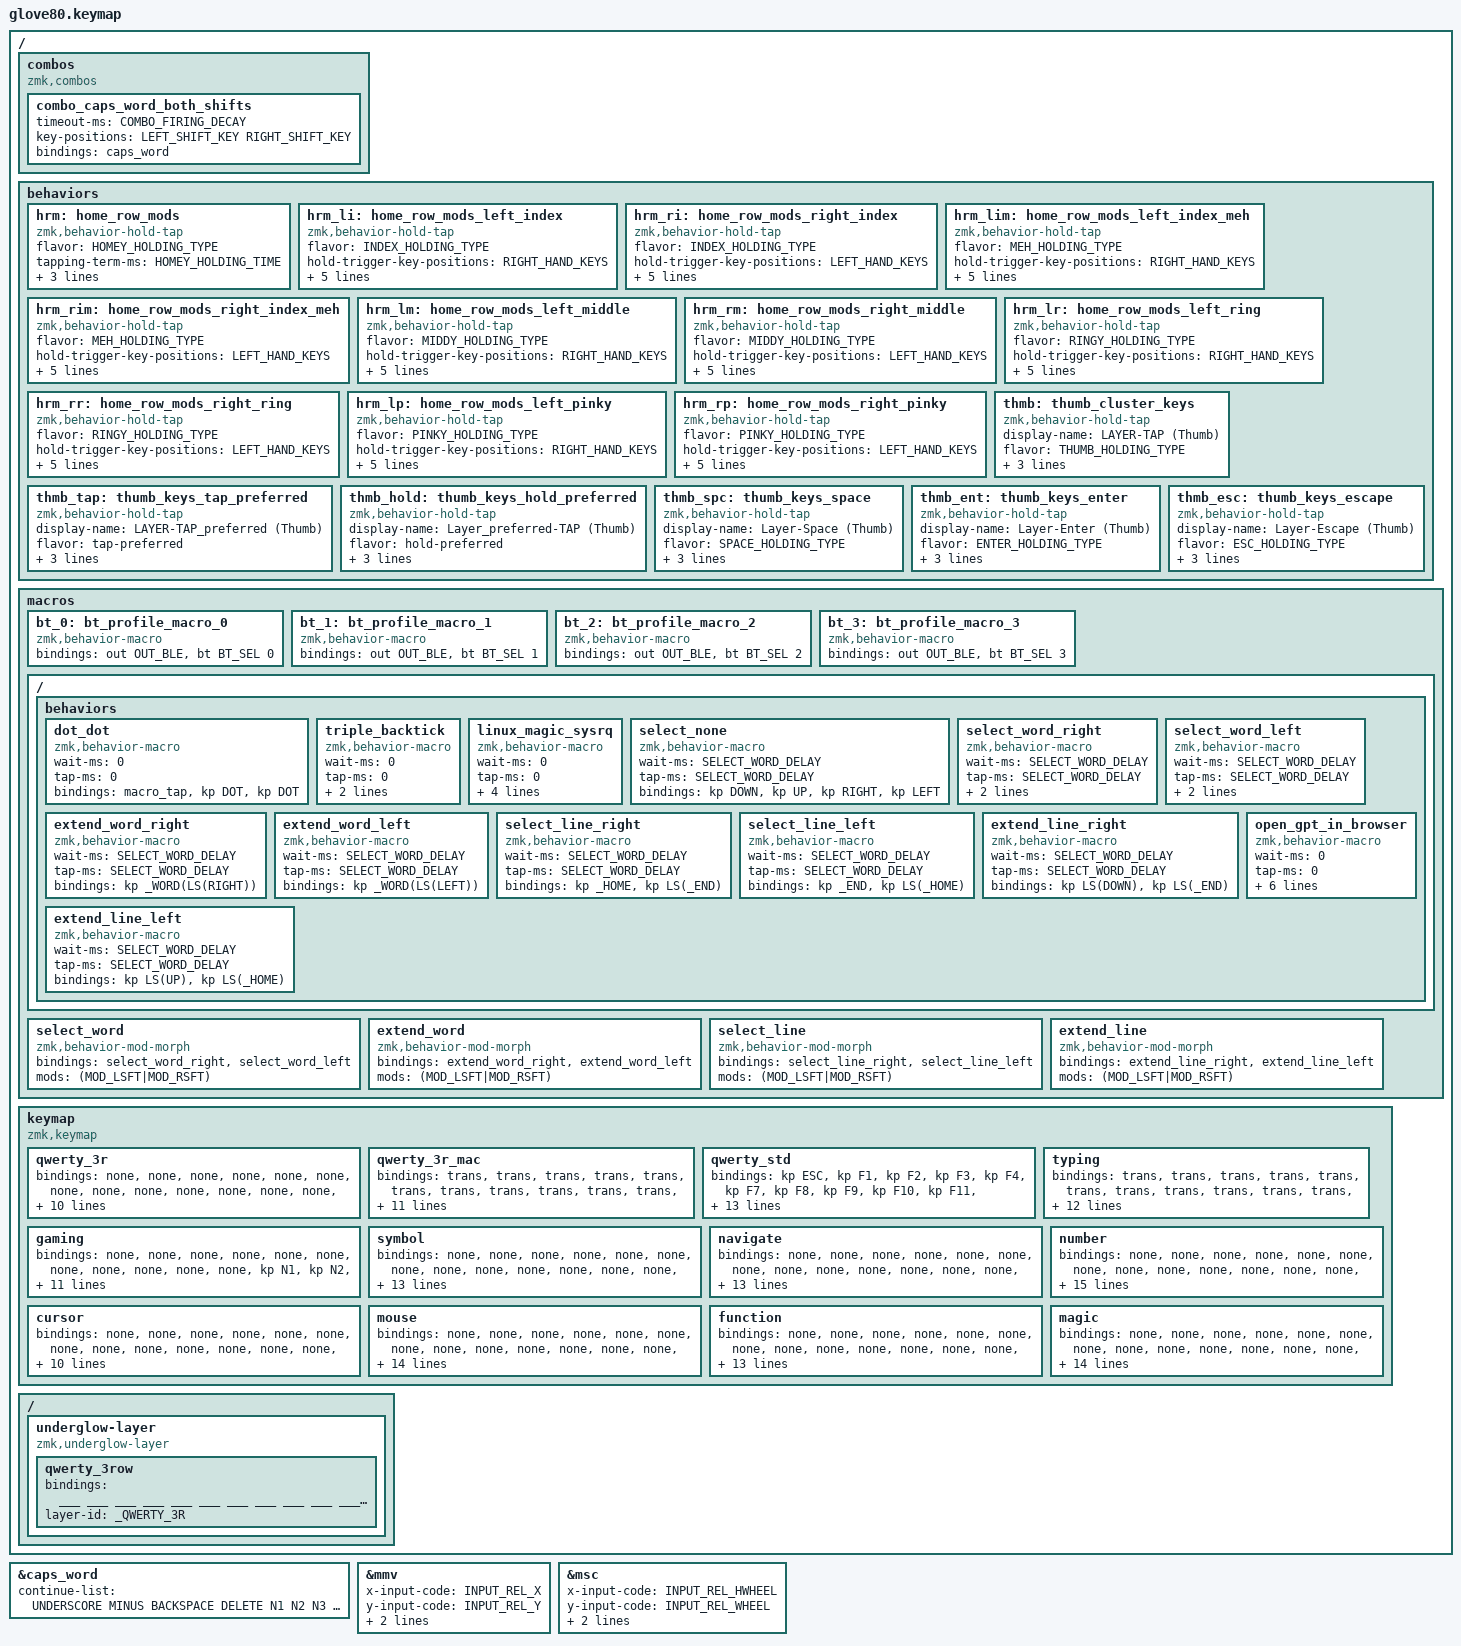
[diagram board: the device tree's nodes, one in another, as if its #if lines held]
/*
 * Copyright (c) 2020 The ZMK Contributors
 *
 * SPDX-License-Identifier: MIT
 */

// ########################################################################
// Import ZMK Device Tree Bindings
// ########################################################################
#include <behaviors.dtsi>
#include <dt-bindings/zmk/keys.h>
#include <dt-bindings/zmk/bt.h>
#include <dt-bindings/zmk/ext_power.h>
#include <dt-bindings/zmk/outputs.h>
#include <dt-bindings/zmk/rgb.h>

// ------------------------------------------------------------------------
// Mouse Emulation Bindings and configs
// ------------------------------------------------------------------------
#define ZMK_POINTING_DEFAULT_MOVE_VAL 1500  // default: 600
#define ZMK_POINTING_DEFAULT_SCRL_VAL 100    // default: 10

#include <dt-bindings/zmk/pointing.h>

// ########################################################################
// Define Key Positions
// ########################################################################

// ------------------------------------------------------------------------
// Define Key Position for each half
// ------------------------------------------------------------------------

// Glove80 key positions index for positional hold-tap
// - https://discord.com/channels/877392805654306816/937645688244826154/1066713913351221248
// - https://media.discordapp.net/attachments/937645688244826154/1066713913133121556/image.png
//
// |------------------------|------------------------|
// | LEFT_HAND_KEYS         |        RIGHT_HAND_KEYS |
// |                        |                        |
// |  0  1  2  3  4         |          5  6  7  8  9 |
// | 10 11 12 13 14 15      |      16 17 18 19 20 21 |
// | 22 23 24 25 26 27      |      28 29 30 31 32 33 |
// | 34 35 36 37 38 39      |      40 41 42 43 44 45 |
// | 46 47 48 49 50 51      |      58 59 60 61 62 63 |
// | 64 65 66 67 68         |         75 76 77 78 79 |
// |                69 52   |   57 74                |
// |                 70 53  |  56 73                 |
// |                  71 54 | 55 72                  |
// |------------------------|------------------------|
//

#define                                              \
     LEFT_HAND_KEYS                                  \
      0  1  2  3  4                                  \
     10 11 12 13 14 15                               \
     22 23 24 25 26 27                               \
     34 35 36 37 38 39                               \
     46 47 48 49 50 51                               \
     64 65 66 67 68                                  \
                    69 52                            \
                     70 53                           \
                      71 54
#define                                              \
                                     RIGHT_HAND_KEYS \
                                       5  6  7  8  9 \
                                   16 17 18 19 20 21 \
                                   28 29 30 31 32 33 \
                                   40 41 42 43 44 45 \
                                   58 59 60 61 62 63 \
                                      75 76 77 78 79 \
                                57 74                \
                               56 73                 \
                              55 72

// ------------------------------------------------------------------------
// Define Key Position for Home Row Mods (HRMs)
// ------------------------------------------------------------------------
#define LEFT_PINKY_KEY  35
#define LEFT_RINGY_KEY  36
#define LEFT_MIDDY_KEY  37
#define LEFT_INDEX_KEY  38
#define LEFT_MEH_KEY    39

#define RIGHT_MEH_KEY   40
#define RIGHT_INDEX_KEY 41
#define RIGHT_MIDDY_KEY 42
#define RIGHT_RINGY_KEY 43
#define RIGHT_PINKY_KEY 44

// ------------------------------------------------------------------------
// Define Shift Key Positions (used for caps word activation)
// ------------------------------------------------------------------------
#define LEFT_SHIFT_KEY  46
#define RIGHT_SHIFT_KEY 63

// ########################################################################
// Tap-Hold Configs
// ########################################################################

// ------------------------------------------------------------------------
// Set tapping TERMs
// ------------------------------------------------------------------------

// ........................................................................
// Guides
// ........................................................................

// Sunsaku's suggested TAPPING_TERM, based on difficulty:
// LEVEL 0 => sunaku (150ms)
// LEVEL 1 => novice (500ms)
// LEVEL 2 => slower (400ms)
// LEVEL 3 => normal (300ms)
// LEVEL 4 => faster (200ms)
// LEVEL 5 => expert (100ms)

// Tapping FLavors (flavor)
// hold_preferred:         (~QMK's HOLD_ON_OTHER_KEY_PRESS)(Good for Thumb keys)
// balanced:               (~QMK's PERMISSIVE_HOLD)
// tap-preferred:          (~QMK's default)(Good for Legato typing)
// tap-unless-interrupted:

// Quick Tap (quick_tap_ms): it's very useful for HRM keys that double as vim nav keys.

// require-prior-idle-ms: timeout for typing streak enforcement (~QMK's FLOW_TAP_TERM).

// ........................................................................
// migrated from QMK
// ........................................................................
#define TAPPING_TERM   150                   // The duration, after which, a key is considered held. Default: 200 (ms)
#define QUICK_TAP_TERM (TAPPING_TERM - 50)   // Time for "press then hold", for auto-repeat. Default: = TAPPING_TERM
#define FLOW_TAP_TERM  (TAPPING_TERM - 25)   // Disables holds when typing quickly. Default: 125 (ms)

// ........................................................................
// ZMK
// ........................................................................
// FIXME: just use TAPPING_TERM (so Vars used in QMK and ZMK are mutually consistent)
#define TAPPING_RESOLUTION TAPPING_TERM

// Home Row Mods (HRM)
#define HOMEY_HOLDING_TYPE "tap-preferred"             // Options: hold-preferred, balanced, tap-preferred
#define HOMEY_HOLDING_TIME (TAPPING_TERM + 90)         // HRM keys tapping TERM
#define HOMEY_FLOW_DECAY (FLOW_TAP_TERM)             // Defines how long to wait until you can use HRM keys again.
#define HOMEY_REPEAT_DECAY (QUICK_TAP_TERM)  // Time after a tap, during which holding the same key results in auto-repeat.
// CHORD (i.e., opposite-hand)
// FIXME:What is it for???
#define CHORD_HOLDING_TYPE HOMEY_HOLDING_TYPE          // Defines the flavor of ZMK hold-tap flavor for CHORD keys
#define CHORD_HOLDING_TIME TAPPING_RESOLUTION
#define CHORD_FLOW_DECAY HOMEY_FLOW_DECAY
#define CHORD_REPEAT_DECAY HOMEY_REPEAT_DECAY
// INDEX Finger
#define INDEX_HOLDING_TYPE HOMEY_HOLDING_TYPE
#define INDEX_HOLDING_TIME (TAPPING_RESOLUTION + 30)
#define INDEX_FLOW_DECAY HOMEY_FLOW_DECAY
#define INDEX_REPEAT_DECAY HOMEY_REPEAT_DECAY
// MEH Finger (Using Index Finger)
#define MEH_HOLDING_TYPE INDEX_HOLDING_TYPE
#define MEH_HOLDING_TIME (TAPPING_RESOLUTION + 45)
#define MEH_FLOW_DECAY HOMEY_FLOW_DECAY
#define MEH_REPEAT_DECAY HOMEY_REPEAT_DECAY
// MIDDLE Finger
#define MIDDY_HOLDING_TYPE HOMEY_HOLDING_TYPE
#define MIDDY_HOLDING_TIME (TAPPING_RESOLUTION + 60)
#define MIDDY_FLOW_DECAY HOMEY_FLOW_DECAY
#define MIDDY_REPEAT_DECAY HOMEY_REPEAT_DECAY
// RING Finger
#define RINGY_HOLDING_TYPE HOMEY_HOLDING_TYPE
#define RINGY_HOLDING_TIME (TAPPING_RESOLUTION + 90)
#define RINGY_FLOW_DECAY HOMEY_FLOW_DECAY
#define RINGY_REPEAT_DECAY HOMEY_REPEAT_DECAY
// PINKY Finger
#define PINKY_HOLDING_TYPE HOMEY_HOLDING_TYPE
#define PINKY_HOLDING_TIME (TAPPING_RESOLUTION + 120)
#define PINKY_FLOW_DECAY HOMEY_FLOW_DECAY
#define PINKY_REPEAT_DECAY HOMEY_REPEAT_DECAY
// THUMB KEYs
#define THUMB_HOLDING_TYPE "balanced"           // Options: hold-preferred, balanced (sunsaku's pref), tap-preferred
#define THUMB_HOLDING_TIME (TAPPING_TERM + 50)  // THUMB keys tapping TERM
#define THUMB_FLOW_DECAY TAPPING_TERM           // Defines how long to wait until you can use THUMB keys again.
#define THUMB_REPEAT_DECAY (QUICK_TAP_TERM)     // Time after a tap, during which holding the same key results in auto-repeat.
// SPACE thumb key
#define SPACE_HOLDING_TYPE THUMB_HOLDING_TYPE
#define SPACE_HOLDING_TIME (THUMB_HOLDING_TIME - 10)
#define SPACE_FLOW_DECAY THUMB_FLOW_DECAY
#define SPACE_REPEAT_DECAY THUMB_REPEAT_DECAY
// ENTER thumb key
#define ENTER_HOLDING_TYPE THUMB_HOLDING_TYPE
#define ENTER_HOLDING_TIME (THUMB_HOLDING_TIME - 25)
#define ENTER_FLOW_DECAY THUMB_FLOW_DECAY
#define ENTER_REPEAT_DECAY THUMB_REPEAT_DECAY
// ESC thumb key
#define ESC_HOLDING_TYPE THUMB_HOLDING_TYPE
#define ESC_HOLDING_TIME THUMB_HOLDING_TIME
#define ESC_FLOW_DECAY THUMB_FLOW_DECAY
#define ESC_REPEAT_DECAY THUMB_REPEAT_DECAY

// ........................................................................
// Miryoku
// ........................................................................
// TODO: too complicated, maybe it's better to just remove it
#define ENFORCE_BILATERAL  // Cancels out single-handed HRMs activation and replacing them with taps.

// ###############################################################
// Define Aliases
// ###############################################################

// ---------------------------------------------------------------
// Define Aliases: Layers
// ---------------------------------------------------------------
// NOTE: These are just aliases for layer numbers. The actual layer numbers are determined by the order of the layers in the keymap.
// If you change the order of the layers, you must also change the layer numbers below.

/* #define DEFAULT           0   // Glove80 default layer */
/* #define LOWER             1   // Glove80 lower layer */
/* #define MAGIC             2   // Glove80 magic layer */
#define _QWERTY_3R         0   // TekBoArt Base QWERTY layer (3-row)
#define _QWERTY_3R_MAC     1   // TekBoArt Base QWERTY layer (3-row)
#define _QWERTY_STD        2   // TekBoArt Base Standard layer
#define _TYPING            3   // TekBoArt Typing layer
#define _GAMING            4   // TekBoArt Gaming layer
#define _SYMBOL            5   // TekBoArt Symbol layer
#define _NAVIGATE          6   // TekBoArt Symbol layer
#define _NUMBER            7   // TekBoArt Number layer
#define _CURSOR            8   // TekBoArt Cursor layer
#define _MOUSE             9   // TekBoArt Cursor layer
#define _FUNCTION          10   // TekBoArt Function layer
#define _MAGIC             11  // Tekboart magic layer

// ---------------------------------------------------------------
// Define Aliases: Layer Switch/Activation
// ---------------------------------------------------------------
// (Base) QWERTY Layer (3-row)
#define TG_BASE  &tog _QWERTY_3R
#define TO_BASE  &to  _QWERTY_3R

// (Base) QWERTY Layer (3-row) -- MacOS
#define TG_BSMC  &tog _QWERTY_3R_MAC
#define TO_BSMC  &to  _QWERTY_3R_MAC

// (Base) QWERTY Layer (6-row)
#define TG_STD   &tog _QWERTY_STD
#define TO_STD   &to  _QWERTY_STD

// Typing Layer
#define TG_TYP   &tog _TYPING
#define TO_TYP   &to  _TYPING

// Gaming Layer
#define TG_GAME  &tog _GAMING
#define TO_GAME  &to  _GAMING

// --- Thumb Layer ---
// Symbol Layer
#define LT_SYM      &thmb_ent  _SYMBOL RET
#define LT_SYM_NAV  &thmb      _SYMBOL SM_BSLS  // SYM layer accessed through the NAV layer
#define MO_SYM      &mo        _SYMBOL
#define TG_SYM      &tog       _SYMBOL
#define TO_SYM      &to        _SYMBOL

// Navigation Layer
#define LT_NAV      &thmb_spc  _NAVIGATE SPC
#define LT_NAV_SYM  &thmb      _NAVIGATE SM_ADS // NAV layer accessed through the SYM layer
#define MO_NAV      &mo        _NAVIGATE
#define TG_NAV      &tog       _NAVIGATE
#define TO_NAV      &to        _NAVIGATE

// Number Layer
#define LT_NUM   &thmb_tap  _NUMBER TAB
#define MO_NUM   &mo  _NUMBER
#define TG_NUM   &tog _NUMBER
#define TO_NUM   &to  _NUMBER

// Cursor Layer
#define LT_CSR   &thmb_hold  _CURSOR N1
#define MO_CSR   &mo  _CURSOR
#define TG_CSR   &tog _CURSOR
#define TO_CSR   &to  _CURSOR

// Mouse Layer
#define LT_MSE   &thmb_hold  _MOUSE N1
#define MO_MSE   &mo  _MOUSE
#define TG_MSE   &tog _MOUSE
#define TO_MSE   &to  _MOUSE

// Function Layer
#define LT_FN    &thmb_esc  _FUNCTION ESC
#define MO_FN    &mo  _FUNCTION
#define TG_FN    &tog _FUNCTION
#define TO_FN    &to  _FUNCTION

// Magic Layer
#define MO_MGC   &mo  _MAGIC
#define TG_MGC   &tog _MAGIC
#define TO_MGC   &to  _MAGIC

// ------- Define Aliases: Mod-Tap Keys  -------
#define MT_LSFT &mt LSHIFT LBKT
#define MT_RSFT &mt RSHIFT RBKT
#define MT_RALT &mt RALT TAB

// ------- Define Aliases: Sticky Keys  -------
// Sticky keys remain active until the next key is pressed.
// They are useful for one-handed typing, e.g., first letter capital.
// Sticky Mods (OSM)
#define ST_LSFT &sk LSHIFT
#define ST_RSFT &sk RSHIFT


// ------- Define Aliases: Modifier Combinations  -------
#define MEH_L LA(LC(LSHFT))
#define MEH_R RA(RC(RSHFT))

// ------- Define Aliases: Home Row Mods (HRMs) -------
// for Win/Linux
#define HRW_LP   &hrm_lp  LGUI   A
#define HRW_LR   &hrm_lr  LALT   S
#define HRW_LM   &hrm_lm  LCTRL  D
#define HRW_LI   &hrm_li  LSHFT  F
#define HRW_LME  &hrm_lim MEH_L  G
#define HRW_RME  &hrm_rim MEH_R  H
#define HRW_RI   &hrm_ri  RSHFT  J
#define HRW_RM   &hrm_rm  RCTRL  K
#define HRW_RR   &hrm_rr  RALT   L
#define HRW_RP   &hrm_rp  RGUI   SEMI
// for MAC
#define HRM_LP   &hrm_lp  LCTRL  A
#define HRM_LR   &hrm_lr  LALT   S
#define HRM_LM   &hrm_lm  LGUI   D
#define HRM_LI   &hrm_li  LSHFT  F
#define HRM_LME  &hrm_lim MEH_L  G
#define HRM_RME  &hrm_rim MEH_R  H
#define HRM_RI   &hrm_ri  RSHFT  J
#define HRM_RM   &hrm_rm  RGUI   K
#define HRM_RR   &hrm_rr  RALT   L
#define HRM_RP   &hrm_rp  RCTRL  SEMI

// ------- Define Aliases: Symbols -------
#define SM_EXCL  EXCL // !
#define SM_ADS   AT // @
#define SM_HASH  HASH // #
#define SM_DLR   DLLR // $
#define SM_PERC  PRCNT // %
#define SM_CRET  CARET // ^
#define SM_AMPS  AMPS // &
#define SM_ASTR  ASTERISK // *
#define SM_LPRN  LPAR // (
#define SM_RPRN  RPAR // )
#define SM_LBRC  LBKT // [
#define SM_RBRC  RBKT // ]
#define SM_LCBR  LBRC // {
#define SM_RCBR  RBRC // }
#define SM_TICK  GRAVE // `
#define SM_TILD  TILDE // ~
#define SM_COMM  COMMA // ,
#define SM_LT    LT // <
#define SM_DOT   DOT // .
#define SM_GT    GT // >
#define SM_SLSH  FSLH // /
#define SM_QUES  QMARK // ?
#define SM_BSLS  BSLH // \ Backslash
#define SM_PIPE  PIPE // |
#define SM_COLN  COLON // :
#define SM_SCLN  SEMI // ;
#define SM_DQT   DQT // "
#define SM_QUOT  SQT // '
#define SM_EQL   EQUAL // =
#define SM_PLUS  PLUS // +
#define SM_MINS  MINUS // -
#define SM_UNDS  UNDER // _

// ------- Define Aliases: Media keys  -------
#define MD_MUTE  C_MUTE
#define MD_VOLU  C_VOL_UP
#define MD_VOLD  C_VOL_DN
#define MD_MPLY  C_PLAY_PAUSE
#define MD_MPRV  C_PREV
#define MD_MNXT  C_NEXT

// ------- Define Aliases: Misc keys  -------

// ---------------------------------------------------------------
// Define Aliases: OS specific actions
// ---------------------------------------------------------------
// Based on Sunsaku's: https://github.com/sunaku/glove80-keymaps
//
// OPERATING_SYSTEM defines which operating system you intend to use
// with this keymap, because shortcuts vary across operating systems.
//
// - https://zmk.dev/docs/codes
// - https://en.wikipedia.org/wiki/Table_of_keyboard_shortcuts
//
// This setting also affects the UNICODE() function defined below, as
// each OS has different shortcuts for typing Unicode hex characters.
//
// NOTE: You may need to enable Unicode hexadecimal input in your OS:
// - (macOS) https://uknowit.uwgb.edu/page.php?id=22623
//     and   https://github.com/ldanet/unicode-hex-input-fix
// - (Linux) https://help.ubuntu.com/stable/ubuntu-help/tips-specialchars.html.en#ctrlshiftu
// - (Windows) https://github.com/samhocevar/wincompose
//
// Specifically, Windows users should be running the WinCompose tool,
// which lets you type Unicode characters via hexadecimal codepoints.
//

// ...............................................................
// Define your preferred operating system
// ...............................................................
// TODO: can we detect the OS automatically? (like QMK does)
#ifndef OPERATING_SYSTEM
  #define OPERATING_SYSTEM 'L' // linux
//#define OPERATING_SYSTEM 'M' // macos
//#define OPERATING_SYSTEM 'W' // windows
#endif

// ...............................................................
// Define Windows, MacOS, and Linux specific key aliases
// ...............................................................
#if OPERATING_SYSTEM == 'W'
  #define _LOCK   LG(L)
#elif OPERATING_SYSTEM == 'M'
  #define _LOCK   _C(LC(Q))
#elif OPERATING_SYSTEM == 'L'
  #define _LOCK   K_LOCK
#endif

// ...............................................................
// Define Aliases that are different for MacOS, but similr for Linux and Windows
// ...............................................................
#if OPERATING_SYSTEM == 'M'
  #define _C      LG
  #define _POWER  K_POWER
  #define _GLOBE  GLOBE

  // The Text modifier--used for Getreuer's Select Word
  #define _WORD   LA

  // Define Aliases: Apps
  #define AP_FFOX ???
  #define AP_CHRM ???
  #define AP_TERM ???
  #define AP_FEXP &kp LS(LA(M))
  #define AP_SSHT LG(LS(N4))
  #define AP_EMOJ LA(LC(SPACE))
  #define AP_CALC  ???

  // Define Aliases: Editing
  #define _HOME   LG(LEFT)
  #define _END    LG(RIGHT)

#else
  #define _C      LC
  #define _POWER  C_POWER
  #define _GLOBE  LGUI

  // The Text modifier--used for Getreuer's Select Word
  #define _WORD   LC

  // Define Aliases: Apps
  #define AP_FFOX  LC(LA(LS(N1)))
  #define AP_CHRM  LC(LA(LS(N2)))
  #define AP_TERM  LC(LA(T))
  #define AP_FEXP  LG(E)
  #define AP_SSHT  LG(LS(S))
  #define AP_EMOJ  LG(DOT)
  #define AP_CALC  K_CALC

  // Define Aliases: Editing
  #define _HOME   HOME
  #define _END    END

#endif

// ...............................................................
// Define Aliases that are shared between MacOS, Linux, and Windows
// ...............................................................
#define _SLEEP      C_SLEEP

// ...............................................................
// Define Aliases that use os-agnostic custom aliases (defined above)
//
// e.g., _C is used for Ctrl on Linux/Windows and Cmd on MacOS
// ...............................................................

// Define Aliases: Editing
#define _UNDO       _C(Z)
#define _REDO       _C(LS(Z))
#define _CUT        _C(X)
#define _COPY       _C(C)
#define _PASTE      _C(V)
#define _FIND       _C(F)
#define _FIND_NEXT  _C(G)
#define _FIND_PREV  _C(LS(G))

// ########################################################################
// ZMK global overrides
// ########################################################################

// ------------------------------------------------------------------------
// CapsWord - ported from Pascal Getreuer's extension for QMK
// ------------------------------------------------------------------------

// - https://zmk.dev/docs/behaviors/caps-word
// - https://getreuer.info/posts/keyboards/caps-word/index.html
&caps_word {
  continue-list = <
    UNDERSCORE MINUS
    BACKSPACE DELETE
    N1 N2 N3 N4 N5 N6 N7 N8 N9 N0
    KP_N1 KP_N2 KP_N3 KP_N4 KP_N5 KP_N6 KP_N7 KP_N8 KP_N9 KP_N0
  >;
};


// ------------------------------------------------------------------------
// Mouse emulation
// ------------------------------------------------------------------------

// ------------------------------------------------------------------------
// Mouse Movement
// ------------------------------------------------------------------------
&mmv {
    x-input-code = <INPUT_REL_X>;
    y-input-code = <INPUT_REL_Y>;
    time-to-max-speed-ms = <300>;
    acceleration-exponent = <1>;
};

// ------------------------------------------------------------------------
// Mouse Scroll
// ------------------------------------------------------------------------
&msc {
    x-input-code = <INPUT_REL_HWHEEL>;
    y-input-code = <INPUT_REL_WHEEL>;
    time-to-max-speed-ms = <300>;
    acceleration-exponent = <0>;
};

/ {
    // ########################################################################
    // Define Custom Conditional Layers
    // ########################################################################
    // conditional_layers {
    //
    // TODO: Add Mac-specific keymaps and choose the appropiate one based on the base layer
    // e.g., if the base layer is _QWERTY_3R_MAC, then use _FUNCTION_MAC, else use _FUNCTION--the same goes for all the layers that have MAC-Specific keymaps.
    // NOTE: BUUUUUT, this way I need different versions of aliases, e.g., _HOME and _HOME_MAC.
    // };

    // ########################################################################
    // Define Custom Combinations (Combos)
    // ########################################################################
    combos {
        // -------------------------------------------------------
        // Adapted from Sunsaku's Glove80 keymap
        //
        // -  https://github.com/sunaku/glove80-keymaps/blob/main/keymap.dtsi
        // -------------------------------------------------------
        compatible = "zmk,combos";

        //
        // COMBO_FIRING_DECAY defines how much time you have left (milliseconds)
        // after pressing the first key in a ZMK combo to finish the whole chord.
        //
        #ifndef COMBO_FIRING_DECAY
        #define COMBO_FIRING_DECAY 80
        #endif

        //
        // SHIFT_FIRING_DECAY defines how much time you have left (milliseconds)
        // after pressing the first key in the one-shot sticky shift ZMK combo
        // (on index finger home + thumb cluster T1) to finish the whole chord.
        //
        #ifndef SHIFT_FIRING_DECAY
        #define SHIFT_FIRING_DECAY 50
        #endif

        // .......................................................
        // Caps Word Activation combo
        // .......................................................
        combo_caps_word_both_shifts {
            timeout-ms = <COMBO_FIRING_DECAY>;
            key-positions = <LEFT_SHIFT_KEY RIGHT_SHIFT_KEY>;
            bindings = <&caps_word>;
        };

        // TODO: Pressing magic key twice, will light up the assigned keys in magic key.

    };

    // ########################################################################
    // Define Custom behaviors
    // ########################################################################
    behaviors {
      // ------------------------------------------------------------------------
      //
      // Miryoku layers and home row mods (adapted from Sunsaku's Glove80 keymap)
      //
      // - https://sunaku.github.io/home-row-mods.html#porting-to-zmk
      // - https://github.com/urob/zmk-config#timeless-homerow-mods
      //
      // ------------------------------------------------------------------------

      // hrm
      hrm: home_row_mods {
          compatible = "zmk,behavior-hold-tap";
          flavor = HOMEY_HOLDING_TYPE;
          tapping-term-ms = <HOMEY_HOLDING_TIME>;
          quick-tap-ms = <HOMEY_REPEAT_DECAY>;
          require-prior-idle-ms = <HOMEY_FLOW_DECAY>;
          #binding-cells = <2>;
          bindings = <&kp>, <&kp>;
      };

      // hrm_index_finger (left)
      hrm_li: home_row_mods_left_index {
          compatible = "zmk,behavior-hold-tap";
          flavor = INDEX_HOLDING_TYPE;
          hold-trigger-key-positions = <RIGHT_HAND_KEYS>;
          hold-trigger-on-release; // wait for other home row mods
          tapping-term-ms = <INDEX_HOLDING_TIME>;
          quick-tap-ms = <INDEX_REPEAT_DECAY>;
          require-prior-idle-ms = <INDEX_FLOW_DECAY>;
          #binding-cells = <2>;
          bindings = <&kp>, <&kp>;
      };

      // hrm_index_finger (right)
      hrm_ri: home_row_mods_right_index {
          compatible = "zmk,behavior-hold-tap";
          flavor = INDEX_HOLDING_TYPE;
          hold-trigger-key-positions = <LEFT_HAND_KEYS>;
          hold-trigger-on-release; // wait for other home row mods
          tapping-term-ms = <INDEX_HOLDING_TIME>;
          quick-tap-ms = <INDEX_REPEAT_DECAY>;
          require-prior-idle-ms = <INDEX_FLOW_DECAY>;
          #binding-cells = <2>;
          bindings = <&kp>, <&kp>;
      };

      // hrm_index_finger_meh (left)
      hrm_lim: home_row_mods_left_index_meh {
          compatible = "zmk,behavior-hold-tap";
          flavor = MEH_HOLDING_TYPE;
          hold-trigger-key-positions = <RIGHT_HAND_KEYS>;
          hold-trigger-on-release; // wait for other home row mods
          tapping-term-ms = <MEH_HOLDING_TIME>;
          quick-tap-ms = <MEH_REPEAT_DECAY>;
          require-prior-idle-ms = <MEH_FLOW_DECAY>;
          #binding-cells = <2>;
          bindings = <&kp>, <&kp>;
      };

      // hrm_index_finger_meh (right)
      hrm_rim: home_row_mods_right_index_meh {
          compatible = "zmk,behavior-hold-tap";
          flavor = MEH_HOLDING_TYPE;
          hold-trigger-key-positions = <LEFT_HAND_KEYS>;
          hold-trigger-on-release; // wait for other home row mods
          tapping-term-ms = <MEH_HOLDING_TIME>;
          quick-tap-ms = <MEH_REPEAT_DECAY>;
          require-prior-idle-ms = <MEH_FLOW_DECAY>;
          #binding-cells = <2>;
          bindings = <&kp>, <&kp>;
      };

      // hrm_middle_finger (left)
      hrm_lm: home_row_mods_left_middle {
          compatible = "zmk,behavior-hold-tap";
          flavor = MIDDY_HOLDING_TYPE;
          hold-trigger-key-positions = <RIGHT_HAND_KEYS>;
          hold-trigger-on-release; // wait for other home row mods
          tapping-term-ms = <MIDDY_HOLDING_TIME>;
          quick-tap-ms = <MIDDY_REPEAT_DECAY>;
          require-prior-idle-ms = <MIDDY_FLOW_DECAY>;
          #binding-cells = <2>;
          bindings = <&kp>, <&kp>;
      };

      // hrm_middle_finger (right)
      hrm_rm: home_row_mods_right_middle {
          compatible = "zmk,behavior-hold-tap";
          flavor = MIDDY_HOLDING_TYPE;
          hold-trigger-key-positions = <LEFT_HAND_KEYS>;
          hold-trigger-on-release; // wait for other home row mods
          tapping-term-ms = <MIDDY_HOLDING_TIME>;
          quick-tap-ms = <MIDDY_REPEAT_DECAY>;
          require-prior-idle-ms = <MIDDY_FLOW_DECAY>;
          #binding-cells = <2>;
          bindings = <&kp>, <&kp>;
      };

      // hrm_ring_finger (left)
      hrm_lr: home_row_mods_left_ring {
          compatible = "zmk,behavior-hold-tap";
          flavor = RINGY_HOLDING_TYPE;
          hold-trigger-key-positions = <RIGHT_HAND_KEYS>;
          hold-trigger-on-release; // wait for other home row mods
          tapping-term-ms = <RINGY_HOLDING_TIME>;
          quick-tap-ms = <RINGY_REPEAT_DECAY>;
          require-prior-idle-ms = <RINGY_FLOW_DECAY>;
          #binding-cells = <2>;
          bindings = <&kp>, <&kp>;
      };

      // hrm_ring_finger (right)
      hrm_rr: home_row_mods_right_ring {
          compatible = "zmk,behavior-hold-tap";
          flavor = RINGY_HOLDING_TYPE;
          hold-trigger-key-positions = <LEFT_HAND_KEYS>;
          hold-trigger-on-release; // wait for other home row mods
          tapping-term-ms = <RINGY_HOLDING_TIME>;
          quick-tap-ms = <RINGY_REPEAT_DECAY>;
          require-prior-idle-ms = <RINGY_FLOW_DECAY>;
          #binding-cells = <2>;
          bindings = <&kp>, <&kp>;
      };

      // hrm_pinky_finger (left)
      hrm_lp: home_row_mods_left_pinky {
          compatible = "zmk,behavior-hold-tap";
          flavor = PINKY_HOLDING_TYPE;
          hold-trigger-key-positions = <RIGHT_HAND_KEYS>;
          hold-trigger-on-release; // wait for other home row mods
          tapping-term-ms = <PINKY_HOLDING_TIME>;
          quick-tap-ms = <PINKY_REPEAT_DECAY>;
          require-prior-idle-ms = <PINKY_FLOW_DECAY>;
          #binding-cells = <2>;
          bindings = <&kp>, <&kp>;
      };

      // hrm_pinky_finger (right)
      hrm_rp: home_row_mods_right_pinky {
          compatible = "zmk,behavior-hold-tap";
          flavor = PINKY_HOLDING_TYPE;
          hold-trigger-key-positions = <LEFT_HAND_KEYS>;
          hold-trigger-on-release; // wait for other home row mods
          tapping-term-ms = <PINKY_HOLDING_TIME>;
          quick-tap-ms = <PINKY_REPEAT_DECAY>;
          require-prior-idle-ms = <PINKY_FLOW_DECAY>;
          #binding-cells = <2>;
          bindings = <&kp>, <&kp>;
      };

      // thumb
      thmb: thumb_cluster_keys {
          compatible = "zmk,behavior-hold-tap";
          display-name = "LAYER-TAP (Thumb)";
          flavor = THUMB_HOLDING_TYPE;
          tapping-term-ms = <THUMB_HOLDING_TIME>;
          quick-tap-ms = <THUMB_REPEAT_DECAY>;
          #binding-cells = <2>;
          bindings = <&mo>, <&kp>;
      };

      // THUMB cluster keys
      // NOTE: Don't use `require-prior-idle-ms` for thumb keys, as it make them part of the flow, hence unwanted taps.

      // thumb tap
      thmb_tap: thumb_keys_tap_preferred {
          compatible = "zmk,behavior-hold-tap";
          display-name = "LAYER-TAP_preferred (Thumb)";
          flavor = "tap-preferred";
          tapping-term-ms = <THUMB_HOLDING_TIME>;
          quick-tap-ms = <THUMB_REPEAT_DECAY>;
          #binding-cells = <2>;
          bindings = <&mo>, <&kp>;
      };

      // thumb hold
      thmb_hold: thumb_keys_hold_preferred {
          compatible = "zmk,behavior-hold-tap";
          display-name = "Layer_preferred-TAP (Thumb)";
          flavor = "hold-preferred";
          tapping-term-ms = <THUMB_HOLDING_TIME>;
          quick-tap-ms = <THUMB_REPEAT_DECAY>;
          #binding-cells = <2>;
          bindings = <&mo>, <&kp>;
      };

      // thumb (tap: space)
      thmb_spc: thumb_keys_space {
          compatible = "zmk,behavior-hold-tap";
          display-name = "Layer-Space (Thumb)";
          flavor = SPACE_HOLDING_TYPE;
          tapping-term-ms = <SPACE_HOLDING_TIME>;  // I found 14Oms to be a good tradeoff.
          quick-tap-ms = <SPACE_REPEAT_DECAY>;
          #binding-cells = <2>;
          bindings = <&mo>, <&kp>;
      };

      // thumb (tap: enter)
      thmb_ent: thumb_keys_enter {
          compatible = "zmk,behavior-hold-tap";
          display-name = "Layer-Enter (Thumb)";
          flavor = ENTER_HOLDING_TYPE;
          tapping-term-ms = <ENTER_HOLDING_TIME>;  // I found 125ms to a good tradeoff.
          quick-tap-ms = <ENTER_REPEAT_DECAY>;
          #binding-cells = <2>;
          bindings = <&mo>, <&kp>;
      };

      // thumb (tap: escape)
      thmb_esc: thumb_keys_escape {
          compatible = "zmk,behavior-hold-tap";
          display-name = "Layer-Escape (Thumb)";
          flavor = ESC_HOLDING_TYPE;
          tapping-term-ms = <ESC_HOLDING_TIME>;  // I found 130ms to a good tradeoff.
          quick-tap-ms = <ESC_REPEAT_DECAY>;
          #binding-cells = <2>;
          bindings = <&mo>, <&kp>;
      };

    };

    // ########################################################################
    // Macros
    // ########################################################################
    macros {

        // -------------------------------------------------------
        // Glove80 Bluetooth buttons
        // -------------------------------------------------------
        bt_0: bt_profile_macro_0 {
            compatible = "zmk,behavior-macro";
            #binding-cells = <0>;
            bindings
                = <&out OUT_BLE>,
                  <&bt BT_SEL 0>;
        };
        #define BT_PRF0 &bt_0

        bt_1: bt_profile_macro_1 {
            compatible = "zmk,behavior-macro";
            #binding-cells = <0>;
            bindings
                = <&out OUT_BLE>,
                  <&bt BT_SEL 1>;
        };
        #define BT_PRF1 &bt_1

        bt_2: bt_profile_macro_2 {
            compatible = "zmk,behavior-macro";
            #binding-cells = <0>;
            bindings
                = <&out OUT_BLE>,
                  <&bt BT_SEL 2>;
        };
        #define BT_PRF2 &bt_2

        bt_3: bt_profile_macro_3 {
            compatible = "zmk,behavior-macro";
            #binding-cells = <0>;
            bindings
                = <&out OUT_BLE>,
                  <&bt BT_SEL 3>;
        };
        #define BT_PRF3 &bt_3

        // -------------------------------------------------------
        // Copied from Sunsaku's Glove80 keymap
        //
        // -  https://github.com/sunaku/glove80-keymaps/blob/main/keymap.dtsi
        // -------------------------------------------------------

        // .......................................................
        // Output two dots
        // .......................................................
        ZMK_MACRO(dot_dot,
            wait-ms = <0>;
            tap-ms = <0>;
            bindings = <&macro_tap &kp DOT &kp DOT>;
        )

        // .......................................................
        // Output three backticks (```), used for code blocks in Markdown or other formats.
        // .......................................................

        ZMK_MACRO(triple_backtick,
            wait-ms = <0>;
            tap-ms = <0>;
            bindings = <&macro_tap &kp GRAVE &kp GRAVE &kp GRAVE>;
        )
        #define MC_TICK &triple_backtick

        // .......................................................
        // Linux Magic System Request Key - hold this down and type REISUB
        //
        // - https://www.kernel.org/doc/html/latest/admin-guide/sysrq.html
        // - https://github.com/manna-harbour/miryoku/discussions/259
        // - https://unix.stackexchange.com/a/143955 (use LALT, not RALT)
        // .......................................................
        ZMK_MACRO(linux_magic_sysrq,
            wait-ms = <0>;
            tap-ms = <0>;
            bindings
            = <&macro_press &mo 0 &kp LALT>
            , <&macro_tap &kp PRINTSCREEN>
            , <&macro_pause_for_release>
            , <&macro_release &mo 0 &kp LALT>
            ;
        )

        // -------------------------------------------------------
        //
        // Approximation of Pascal Getreuer's Select Word macro from QMK
        // - https://getreuer.info/posts/keyboards/select-word/index.html
        //
        // -------------------------------------------------------

        // SELECT_WORD_DELAY defines how long the macro waits (milliseconds)
        // after moving the cursor before it selects a word.  A larger delay
        // may allow the macro to move to the next word upon each invocation.
        #ifndef SELECT_WORD_DELAY
        #define SELECT_WORD_DELAY 1
        #endif

        #define select_all kp _C(A)
        #define SEL_ALL &select_all

        ZMK_MACRO(select_none,
            wait-ms = <SELECT_WORD_DELAY>;
            tap-ms = <SELECT_WORD_DELAY>;
            bindings = <&kp DOWN &kp UP &kp RIGHT &kp LEFT>;
        )

        // select a word (jumps to next word upon each successive invocation)
        select_word: select_word {
            compatible = "zmk,behavior-mod-morph";
            #binding-cells = <0>;
            bindings = <&select_word_right>, <&select_word_left>;
            mods = <(MOD_LSFT|MOD_RSFT)>;
        };
        ZMK_MACRO(select_word_right,
            wait-ms = <SELECT_WORD_DELAY>;
            tap-ms = <SELECT_WORD_DELAY>;
            bindings = <&kp _WORD(RIGHT) &kp _WORD(LEFT) &kp _WORD(LS(RIGHT))>;
        )
        ZMK_MACRO(select_word_left,
            wait-ms = <SELECT_WORD_DELAY>;
            tap-ms = <SELECT_WORD_DELAY>;
            bindings = <&kp _WORD(LEFT) &kp _WORD(RIGHT) &kp _WORD(LS(LEFT))>;
        )
        // FIXME: The SEL_WRD does not extend the selection by repeated presses, as it would in QMK.
        #define SEL_WRD &select_word

        // extend current selection by one word
        extend_word: extend_word {
            compatible = "zmk,behavior-mod-morph";
            #binding-cells = <0>;
            bindings = <&extend_word_right>, <&extend_word_left>;
            mods = <(MOD_LSFT|MOD_RSFT)>;
        };
        ZMK_MACRO(extend_word_right,
            wait-ms = <SELECT_WORD_DELAY>;
            tap-ms = <SELECT_WORD_DELAY>;
            bindings = <&kp _WORD(LS(RIGHT))>;
        )
        ZMK_MACRO(extend_word_left,
            wait-ms = <SELECT_WORD_DELAY>;
            tap-ms = <SELECT_WORD_DELAY>;
            bindings = <&kp _WORD(LS(LEFT))>;
        )

        // select current line
        select_line: select_line {
            compatible = "zmk,behavior-mod-morph";
            #binding-cells = <0>;
            bindings = <&select_line_right>, <&select_line_left>;
            mods = <(MOD_LSFT|MOD_RSFT)>;
        };
        ZMK_MACRO(select_line_right,
            wait-ms = <SELECT_WORD_DELAY>;
            tap-ms = <SELECT_WORD_DELAY>;
            bindings = <&kp _HOME &kp LS(_END)>;
        )
        ZMK_MACRO(select_line_left,
            wait-ms = <SELECT_WORD_DELAY>;
            tap-ms = <SELECT_WORD_DELAY>;
            bindings = <&kp _END &kp LS(_HOME)>;
        )
        #define SEL_LNE &select_line

        //
        // extend current selection by one line
        //
        extend_line: extend_line {
            compatible = "zmk,behavior-mod-morph";
            #binding-cells = <0>;
            bindings = <&extend_line_right>, <&extend_line_left>;
            mods = <(MOD_LSFT|MOD_RSFT)>;
        };
        ZMK_MACRO(extend_line_right,
            wait-ms = <SELECT_WORD_DELAY>;
            tap-ms = <SELECT_WORD_DELAY>;
            bindings = <&kp LS(DOWN) &kp LS(_END)>;
        )
        ZMK_MACRO(extend_line_left,
            wait-ms = <SELECT_WORD_DELAY>;
            tap-ms = <SELECT_WORD_DELAY>;
            bindings = <&kp LS(UP) &kp LS(_HOME)>;
        )


        // -------------------------------------------------------
        // ME macros
        // -------------------------------------------------------
        // .......................................................
        // Open ChatGPT in (default) Browser.
        // .......................................................
        ZMK_MACRO(open_gpt_in_browser,
            wait-ms = <0>;
            tap-ms = <0>;
            bindings
                // Launch or focus Firefox using your existing shortcut.
                = <&kp AP_FFOX>
                // Allow Firefox to start/focus.
                , <&macro_wait_time 1200>
                // Focus the address bar.
                , <&kp LC(L)>
                // Allow the address bar to receive focus.
                , <&macro_wait_time 50>
                // Type the first URL character after the 50 ms delay.
                , <&kp H>
                // Use the normal inter-key delay for the remaining URL.
                , <&macro_wait_time 30>
                // https
                , <&kp T &kp T &kp P &kp S>
                // ://
                , <&kp COLON &kp FSLH &kp FSLH>
                // chatgpt
                , <&kp C &kp H &kp A &kp T>
                , <&kp G &kp P &kp T>
                // .com/
                , <&kp DOT &kp C &kp O &kp M &kp FSLH>
                // Press Enter
                , <&kp ENTER>
                ;
        // };
        )
        #define MC_GPT &open_gpt_in_browser

    };

    // ########################################################################
    // Define Keymaps
    // ########################################################################
    keymap {
        compatible = "zmk,keymap";

        /* <layer_name> { */
        /*     bindings = < */
        /*     &none      &none    &none       &none       &none                                                                                                          &none      &none      &none      &none      &none */
        /*     &none      &none    &none       &none       &none       &none                                                                                   &none      &none      &none      &none      &none      &none */
        /*     &none      &none    &none       &none       &none       &none                                                                                   &none      &none      &none      &none      &none      &none */
        /*     &none      &none    &none       &none       &none       &none                                                                                   &none      &none      &none      &none      &none      &none */
        /*     &none      &none    &none       &none       &none       &none      &none      &none      &none      &none      &none      &none      &none      &none      &none      &none      &none      &none */
        /*     &none      &none    &none       &none       &none                  &none      &none      &none      &none      &none      &none */
        /*     >; */
        /* }; */

        /* default_layer { */
        /*     // --------------------------------------------------------------------------------------------------------------------------------- */
        /*     // |  F1   |  F2  |  F3  |  F4  |  F5  |                                                               |  F6   |  F7   |  F8  |  F9  |  F10 | */
        /*     // |  =    |   1  |   2  |   3  |   4  |  5   |                                                 |  6   |   7   |   8   |   9  |   0  |   -  | */
        /*     // |  TAB  |   Q  |   W  |   E  |   R  |  T   |                                                 |  Y   |   U   |   I   |   O  |   P  |   \  | */
        /*     // |  ESC  |   A  |   S  |   D  |   F  |  G   |                                                 |  H   |   J   |   K   |   L  |   ;  |   '  | */
        /*     // |   `   |   Z  |   X  |   C  |   V  |  B   | LSHFT | LCTRL | LOWER | | LGUI  | RCTRL | RSHFT |  N   |   M   |   ,   |   .  |   /  | PGUP | */
        /*     // | _MAGIC | HOME |  END | LEFT | RIGHT|      | BSPC  | DEL   | LALT  | | RALT  | RET   | SPACE |      |  UP   | DOWN  |   [  |   ]  | PGDN | */
        /*  */
        /*     bindings = < */
            /* &trans    &trans    &trans    &trans    &trans                                                                                    &trans    &trans    &trans    &trans    &trans */
            /* &trans    &trans    &trans    &trans    &trans    &trans                                                                &trans    &trans    &trans    &trans    &trans    &trans */
            /* &trans    &trans    &trans    &trans    &trans    &trans                                                                &trans    &trans    &trans    &trans    &trans    &trans */
            /* &trans    &trans    &trans    &trans    &trans    &trans                                                                &trans    &trans    &trans    &trans    &trans    &trans */
            /* &trans    &trans    &trans    &trans    &trans    &trans    &trans    &trans    &trans    &trans    &trans    &trans    &trans    &trans    &trans    &trans    &trans    &trans */
            /* &trans    &trans    &trans    &trans    &trans              &trans    &trans    &trans    &trans    &trans    &trans              &trans    &trans    &trans    &trans    &trans */
        /*     >; */
        /* }; */

        qwerty_3r {
            bindings = <
            &none     &none     &none     &none     &none                                                                                     &none     &none     &none     &none     &none
            &none     &none     &none     &none     &none     &none                                                                 &none     &none     &none     &none     &none     &none
            &kp LBKT  &kp Q     &kp W     &kp E     &kp R     &kp T                                                                 &kp Y     &kp U     &kp I     &kp O     &kp P     &kp RBKT
            &kp BSPC  HRW_LP    HRW_LR    HRW_LM    HRW_LI    HRW_LME                                                               HRW_RME   HRW_RI    HRW_RM    HRW_RR    HRW_RP    &kp SQT
            ST_LSFT   &kp Z     &kp X     &kp C     &kp V     &kp B     LT_NUM    LT_NAV    &none     &none     LT_SYM    LT_FN     &kp N     &kp M     &kp COMMA &kp DOT   &kp FSLH  ST_RSFT
            MO_MGC    &none     &none     &none     &none               MO_CSR    &none     &none     &none     &none     MO_MSE              &none     &none     &none     &none     MO_MGC
            >;
        };

        qwerty_3r_mac{
            bindings = <
            &trans    &trans    &trans    &trans    &trans                                                                                    &trans    &trans    &trans    &trans    &trans
            &trans    &trans    &trans    &trans    &trans    &trans                                                                &trans    &trans    &trans    &trans    &trans    &trans
            &trans    &trans    &trans    &trans    &trans    &trans                                                                &trans    &trans    &trans    &trans    &trans    &trans
            &trans    HRM_LP    HRM_LR    HRM_LM    HRM_LI    HRM_LME                                                               HRM_RME   HRM_RI    HRM_RM    HRM_RR    HRM_RP    &trans
            &trans    &trans    &trans    &trans    &trans    &trans    &trans    &trans    &trans    &trans    &trans    &trans    &trans    &trans    &trans    &trans    &trans    &trans
            &trans    &trans    &trans    &trans    &trans              &trans    &trans    &trans    &trans    &trans    &trans              &trans    &trans    &trans    &trans    &trans
            >;
        };

        qwerty_std {
            bindings = <
            &kp ESC    &kp F1    &kp F2      &kp F3      &kp F4                                                                                               &kp F7  &kp F8      &kp F9      &kp F10     &kp F11
            &kp GRAVE  &kp N1    &kp N2      &kp N3      &kp N4      &kp N5                                                                           &kp N6  &kp N7  &kp N8      &kp N9      &kp N0      &kp F12
            &kp TAB    &kp Q     &kp W       &kp E       &kp R       &kp T                                                                            &kp Y   &kp U   &kp I       &kp O       &kp P       &kp BSLH
            &kp CAPS   &kp A     &kp S       &kp D       &kp F       &kp G                                                                            &kp H   &kp J   &kp K       &kp L       &kp SEMI    &kp SQT
            &kp LSHIFT &kp Z     &kp X       &kp C       &kp V       &kp B   &kp DEL     &kp HOME   &kp PGUP  &kp RET   &kp UP    &kp BSPC            &kp N   &kp M   &kp COMMA   &kp DOT     &kp FSLH    &kp RSHFT
            MO_MGC     &kp LCTRL &kp LALT    &kp LGUI    &kp F5              &kp SPACE   &kp END    &kp PGDN  &kp LEFT  &kp DOWN  &lt _FUNCTION RIGHT         &kp F6  &kp LBKT    &kp RBKT    &kp MINUS   &kp EQUAL
            >;
        };

        typing {
            bindings = <
            &trans     &trans    &trans      &trans      &trans                                                                                             &trans  &trans      &trans      &trans      &trans
            &trans     &trans    &trans      &trans      &trans      &trans                                                                         &trans  &trans  &trans      &trans      &trans      &trans
            &trans     &trans    &trans      &trans      &trans      &trans                                                                         &trans  &trans  &trans      &trans      &trans      &trans
            &trans     &kp A     &kp S       &kp D       &kp F       &kp G                                                                          &kp H   &kp J   &kp K       &kp L       &kp SEMI    &trans
            &trans     &trans    &trans      &trans      &trans      &trans    &trans      &trans       &trans      &trans     &trans     &trans    &trans  &trans   &trans     &trans      &trans      &trans
            &trans     &trans    &trans      &trans      &trans                &trans      &trans       &trans      &trans     &trans     &trans            &trans   &trans     &trans      &trans      &trans
            >;
        };


        // TODO: Finalize gaming layer to match my QMK
        gaming {
            bindings = <
            &none     &none     &none     &none     &none                                                                                   &none    &none      &none       &none       &none
            &none     &kp N1    &kp N2    &kp N3    &kp N4    &kp N5                                                                &kp N6  &kp N7   &kp N8     &kp N9      &kp N0      &none
            &kp M     &kp TAB   &kp Q     &kp W     &kp E     &kp R                                                                 &none   &none    &kp UP     &none       &none       &none
            &kp I     &kp ESC   &kp A     &kp S     &kp D     &kp F                                                                 &none   &kp LEFT &kp DOWN   &kp RIGHT   &none       &none
            &kp G     &kp LSHFT &kp Z     &kp X     &kp C     &kp V     &kp LALT  LT_NAV    &none     &none     &trans    &trans    &none   &none    &none      &none       &none       &none
            &trans    &none     &none     &none     &none               &kp LGUI  &none     &none     &none     &none     &trans            &none    &none      &none       &none       &trans
            >;
        };

        symbol {
            bindings = <
            &none        &none        &none        &none        &none                                                                                                     &none     &none     &none     &none     &none
            &none        &none        &none        &none        &none         &none                                                                             &none     &none     &none     &none     &none     &none
            &kp SM_EXCL  &kp N1       &kp N2       &kp N3       &kp N4        &kp N5                                                                            &kp N6    &kp N7    &kp N8    &kp N9    &kp N0    &none
            &kp SM_HASH  &kp SM_CRET  &kp SM_EQL   &kp SM_UNDS  &kp SM_DLR    &kp SM_ASTR                                                                       &none     &kp RSHFT &kp RCTRL &kp RALT  &kp RGUI  MC_TICK
            &kp SM_AMPS  &kp SM_LT    &kp SM_PIPE  &kp SM_MINS  &kp SM_GT     &kp SM_PLUS   &kp SM_PERC   LT_NAV_SYM    &trans    &trans    &trans    &trans    &kp TAB   &kp SPC   &kp RET   &kp BSPC  &kp DEL   &none
            &trans       &none        &none        &none        &none                       &trans        &trans        &trans    &trans    &trans    &trans              &none     &none     &none     &none     &trans
            >;
        };

        // TODO: add DEL_NORM
        navigate {
            bindings = <
            &none     &none     &none     &none      &none                                                                                                   &none         &none         &none         &none         &none
            &none     &none     &none     &none      &none       &none                                                                         &none         &none         &none         &none         &none         &none
            &none     &kp N1    &kp N2    &kp N3     &kp N4      &kp N5                                                                        &kp N6        &kp N7        &kp N8        &kp N9        &kp N0        &none
            &kp DEL   &kp LGUI  &kp LALT  &kp LCTRL  &kp LSHFT   SEL_WRD                                                                       &kp _HOME     &kp LEFT      &kp DOWN      &kp UP        &kp RIGHT     &kp _END
            &none     &kp _UNDO &kp _CUT  &kp _COPY  &kp _PASTE  SEL_LNE   &trans    &trans    &trans    &trans    LT_SYM_NAV    &kp SM_TICK   &kp SM_LBRC   &kp SM_LCBR   &kp SM_LPRN   &kp SM_RPRN   &kp SM_RCBR   &kp SM_RBRC
            &trans    &none     &none     &none      &none                 &trans    &trans    &trans    &trans    &trans        &trans                      &none         &none         &none         &none         &trans
            >;
        };

        number {
            bindings = <
            &none        &none      &none      &none      &none                                                                                           &none      &none      &none      &none            &none
            &none        &none      &none      &none      &none       &none                                                                   &none       &none      &none      &none      &none            &none
            &none        &kp DEL    &kp BSPC   &kp RET    &kp SPC     &none                                                                   &kp KP_NUM  &kp KP_N7  &kp KP_N8  &kp KP_N9  &kp COLON        &kp PRCNT
            &kp AP_CALC  &kp LGUI   &kp LALT   &kp LCTRL  &kp LSHFT   SEL_WRD                                                                 &kp LPAR    &kp KP_N4  &kp KP_N5  &kp KP_N6  &kp KP_MINUS     &kp KP_PLUS
            &none        &kp _UNDO  &kp _CUT   &kp _COPY  &kp _PASTE  SEL_LNE   &trans    &trans    &trans    &trans    &kp KP_N0 &kp KP_DOT  &kp RPAR    &kp KP_N1  &kp KP_N2  &kp KP_N3  &kp KP_MULTIPLY  &kp KP_DIVIDE
            &trans       &none      &none      &none      &none                 &trans    &trans    &trans    &trans    &kp KP_N0 &kp KP_DOT              &none      &none      &none      &none            &trans
            >;
        };

        // TODO: implement RENAME
        cursor {
            bindings = <
            &none     &none     &none     &none     &none                                                                                     &none     &none     &none     &none     &none
            &none     &none     &none     &none     &none     &none                                                                 &none     &none     &none     &none     &none     &none
            &none     &none     &none     &none     &none     &none                                                                 &none     &none     &none     &none     &none     &none
            &none     &none     &none     &none     &none     &none                                                                 &none     &none     &none     &none     &none     &none
            &none     &none     &none     &none     &none     &none     &trans    &trans    &trans    &trans    &trans    &trans    &none     &none     &none     &none     &none     &none
            &trans    &none     &none     &none     &none               &trans    &trans    &trans    &trans    &trans    &trans              &none     &none     &none     &none     &trans
            >;
        };

        mouse {
            bindings = <
            &none      &none      &none           &none           &none                                                                                                  &none           &none           &none            &none      &none
            &none      &none      &none           &none           &none            &none                                                                 &none           &none           &none           &none            &none      &none
            &none      &none      &mkp MB4        &msc SCRL_UP    &mkp MB5         &none                                                                 &none           &mkp MB4        &mmv MOVE_UP    &mkp MB5         &none      &none
            &kp K_APP  &kp LCTRL  &msc SCRL_LEFT  &msc SCRL_DOWN  &msc SCRL_RIGHT  &none                                                                 &msc SCRL_UP    &mmv MOVE_LEFT  &mmv MOVE_DOWN  &mmv MOVE_RIGHT  &kp LCTRL  &kp K_APP
            &none      &kp _UNDO  &kp _CUT        &kp _COPY       &kp _PASTE       &none     &mkp MB1  &mkp MB2  &trans    &trans    &trans    &trans    &msc SCRL_DOWN  &mkp MB1        &mkp MB3        &mkp MB2         &none      &none
            &trans     &none      &none           &none           &none                      &mkp MB3  &trans    &trans    &trans    &trans    &trans                    &none           &none           &none            &none      &trans
            >;
        };

        function {
            bindings = <
            &none     &none        &none        &none        &none                                                                                              &none     &none     &none     &none     &none
            &none     &none        &none        &none        &none      &none                                                                     &none         &none     &none     &none     &none     &none
            &kp INS   &kp MD_MUTE  &kp MD_VOLD  &kp MD_VOLU  &none      &kp AP_TERM                                                               &kp AP_SSHT   &kp F7    &kp F8    &kp F9    &kp F10   &kp F13
            &kp CAPS  &kp LGUI     &kp LALT     &kp LCTRL    &kp LSHFT  &kp AP_CHRM                                                               &kp AP_EMOJ   &kp F4    &kp F5    &kp F6    &kp F11   &kp F14
            TG_TYP    &kp MD_MPLY  &kp MD_MPRV  &kp MD_MNXT  MC_GPT     &kp AP_FFOX   &trans    &trans    &trans    &trans    &trans    &trans    &kp AP_FEXP   &kp F1    &kp F2    &kp F3    &kp F12   &kp F15
            &trans    &none        &none        &none        &none                    &trans    &trans    &trans    &trans    &trans    &trans                  &none     &none     &none     &none     &trans
            >;
        };

        magic {
            bindings = <
            &none            &none            &none            &none            &none                                                                                     &none     &none     &none     &none     &none
            &none            &none            &none            &none            &none     &none                                                                 &none     &none     &none     &none     &none     &none
            &rgb_ug RGB_TOG  BT_PRF0          BT_PRF1          BT_PRF2          BT_PRF3   &out OUT_USB                                                          &none     &none     &none     &none     &none     &none
            &bootloader      &rgb_ug RGB_HUI  &rgb_ug RGB_BRI  &rgb_ug RGB_SAI  &none     TG_GAME                                                               &none     &none     &none     &none     &none     &bootloader
            &none            &rgb_ug RGB_HUD  &rgb_ug RGB_BRD  &rgb_ug RGB_SAD  &none     TG_STD    TG_NUM    TG_NAV    &trans    &trans    TG_SYM    TG_FN     TO_BASE   TO_BSMC   &none     &none     &none     &none
            &trans           &none            &none            &none            &none               TG_CSR    &trans    &trans    &trans    &trans    TG_MSE              &none     &none     &none     &none     &trans
            >;
        };

    };

    // ########################################################################
    // Define RGB Layout
    // ########################################################################

    // ------------------------------------------------------------------------
    // Define RGB Colors
    // ------------------------------------------------------------------------
    #if __has_include(<dt-bindings/zmk/rgb_colors.h>)
      // ........................................................................
      // Color definitions with conflict guard to prevent
      // accidental redefinition of common abbreviations.
      // ........................................................................
      #if defined(RED) || defined(RED_RGB) || \
          defined(COR) || defined(COR_RGB) || \
          defined(ORN) || defined(ORN_RGB) || \
          defined(GDN) || defined(GDN_RGB) || \
          defined(GOL) || defined(GOL_RGB) || \
          defined(YLW) || defined(YLW_RGB) || \
          defined(CHU) || defined(CHU_RGB) || \
          defined(GRN) || defined(GRN_RGB) || \
          defined(SPG) || defined(SPG_RGB) || \
          defined(CYN) || defined(CYN_RGB) || \
          defined(AZU) || defined(AZU_RGB) || \
          defined(TEA) || defined(TEA_RGB) || \
          defined(TUR) || defined(TUR_RGB) || \
          defined(BLU) || defined(BLU_RGB) || \
          defined(PUR) || defined(PUR_RGB) || \
          defined(MAJ) || defined(MAJ_RGB) || \
          defined(PNK) || defined(PNK_RGB) || \
          defined(WHT) || defined(WHT_RGB) || \
          defined(BLK) || defined(BLK_RGB) || \
          defined(___) || \
          defined(DUG) || defined(DUG_RGB) || \
          defined(LAC) || defined(LAC_RGB) || \
          defined(BSL) || defined(BNL) || defined(BCL) || \
          defined(SSL) || defined(SNL) || defined(SCL) || \
          defined(FST) || defined(WRP) || defined(SLO)
      #error "Naming conflict: 3-letter color abbreviation already defined!"
      #endif

      // ........................................................................
      // color definitions from QMK
      // https://github.com/qmk/qmk_firmware/blob/master/quantum/color.h
      // ........................................................................
      #define RED_RGB 0xFF0000 // #FF0000 RED      => RED (red)
      #define COR_RGB 0xFF7C4D // #FF7C4D CORAL    => COR (coral)
      #define ORN_RGB 0xFF8000 // #FF8000 ORANGE   => ORN (ornj)
      #define GDN_RGB 0xD9A521 // #D9A521 GOLDNROD => GDN (gold'nrod)
      #define GOL_RGB 0xFFD900 // #FFD900 GOLD     => GOL (gold)
      #define YLW_RGB 0xFFFF00 // #FFFF00 YELLOW   => YLW (yellow)
      #define CHU_RGB 0x80FF00 // #80FF00 CHARTRSE => CHU (chartreuse)
      #define GRN_RGB 0x00FF00 // #00FF00 GREEN    => GRN (green)
      #define SPG_RGB 0x00FF80 // #00FF80 SPRINGRN => SPG (spring green)
      #define CYN_RGB 0x00FFFF // #00FFFF CYAN     => CYN (sigh-an)
      #define AZU_RGB 0x99F5FF // #99F5FF AZURE    => AZU (a-zur)
      #define TEA_RGB 0x008080 // #008080 TEAL     => TEA (teel)
      #define TUR_RGB 0x476E6A // #476E6A TURQUOIS => TUR (turquoise)
      #define BLU_RGB 0x0000FF // #0000FF BLUE     => BLU (bloo)
      #define PUR_RGB 0x7A00FF // #7A00FF PURPLE   => PUR (purp)
      #define MAJ_RGB 0xFF00FF // #FF00FF MAGENTA  => MAJ (mah-jenta)
      #define PNK_RGB 0xFF80BF // #FF80BF PINK     => PNK (pink)
      #define WHT_RGB 0xFFFFFF // #FFFFFF WHITE    => WHT (white)
      #define BLK_RGB 0x000000 // #000000 BLACK    => BLK (blak)

      // ........................................................................
      // color definitions from MoErgo
      // https://github.com/moergo-sc/zmk/blob/aca523dfce9b6447ffd19d833b791d44f1f286de/app/src/rgb_underglow.c#L259-L265
      // ........................................................................
      #define DUG_RGB 0x00ff68 // #00ff68 DULL_GRN => DUG (dull green)
      #define LAC_RGB 0x6b1fce // #6b1fce LILAC    => LAC (lilac)

      // ........................................................................
      // underglow for the colors above
      // ........................................................................
      #define RED &ug RED_RGB
      #define COR &ug COR_RGB
      #define ORN &ug ORN_RGB
      #define GDN &ug GDN_RGB
      #define GOL &ug GOL_RGB
      #define YLW &ug YLW_RGB
      #define CHU &ug CHU_RGB
      #define GRN &ug GRN_RGB
      #define SPG &ug SPG_RGB
      #define CYN &ug CYN_RGB
      #define TUR &ug TUR_RGB
      #define BLU &ug BLU_RGB
      #define PUR &ug PUR_RGB
      #define MAJ &ug MAJ_RGB
      #define PNK &ug PNK_RGB
      #define WHT &ug WHT_RGB
      #define BLK &ug BLK_RGB
      #define ___ &ug BLK_RGB
      #define DUG &ug DUG_RGB
      #define LAC &ug LAC_RGB

      // ........................................................................
      // underglow for keyboard locks on the Base layer
      // ........................................................................
      #define BSL &ug_sl LAC_RGB WHT_RGB // ScrollLock COLOR_OFF COLOR_ON
      #define BNL &ug_nl LAC_RGB WHT_RGB // NumLock    COLOR_OFF COLOR_ON
      #define BCL &ug_cl BLK_RGB WHT_RGB // CapsLock   COLOR_OFF COLOR_ON

      // ........................................................................
      // underglow for keyboard locks on the System layer
      // ........................................................................
      #define SSL &ug_sl BLK_RGB WHT_RGB // ScrollLock COLOR_OFF COLOR_ON
      #define SNL &ug_nl BLK_RGB WHT_RGB // NumLock    COLOR_OFF COLOR_ON
      #define SCL &ug_cl BLK_RGB WHT_RGB // CapsLock   COLOR_OFF COLOR_ON

      // ........................................................................
      // colors for mouse speed scaling in Mouse layers
      // ........................................................................
      #define FST GOL
      #define SLO PNK
      #define WRP CHU

      // ------------------------------------------------------------------------
      // PER-KEY-RGB keymap
      // ------------------------------------------------------------------------
      / {
        underglow-layer {
          compatible  = "zmk,underglow-layer";

          /*
          Template {
            bindings = <
              ___ ___ ___ ___ ___                                             ___ ___ ___ ___ ___
              ___ ___ ___ ___ ___ ___                                     ___ ___ ___ ___ ___ ___
              ___ ___ ___ ___ ___ ___                                     ___ ___ ___ ___ ___ ___
              ___ ___ ___ ___ ___ ___                                     ___ ___ ___ ___ ___ ___
              ___ ___ ___ ___ ___ ___     ___ ___ ___     ___ ___ ___     ___ ___ ___ ___ ___ ___
              ___ ___ ___ ___ ___         ___ ___ ___     ___ ___ ___         ___ ___ ___ ___ ___
            >;
            layer-id = <LAYER_Template>;
          };
          */

          // _QWERTY_3R
          /* #ifdef _QWERTY_3R */
          qwerty_3row {
            bindings = <
              ___ ___ ___ ___ ___                                             ___ ___ ___ ___ ___
              ___ ___ ___ ___ ___ ___                                     ___ ___ ___ ___ ___ ___
              ___ ___ ___ ___ ___ ___                                     ___ ___ ___ ___ ___ ___
              BCL RED RED RED RED ___                                     ___ RED RED RED RED ___
              ___ ___ ___ ___ ___ ___     ___ ___ ___     ___ ___ ___     ___ ___ ___ ___ ___ ___
              ___ ___ ___ ___ ___         ___ ___ ___     ___ ___ ___         ___ ___ ___ ___ ___
            >;
            layer-id = <_QWERTY_3R>;
          };
          /* #endif */

          // _QWERTY_ST
          // _TYPING
          // _GAMING
          // _SYMBOL
          // _NUMBER
          // _CURSOR
          // LOWER
          // _MAGIC
          // _FUNCTION

        };
      };

      #undef RED
      #undef RED_RGB
      #undef COR
      #undef COR_RGB
      #undef ORN
      #undef ORN_RGB
      #undef GDN
      #undef GDN_RGB
      #undef GOL
      #undef GOL_RGB
      #undef YLW
      #undef YLW_RGB
      #undef CHU
      #undef CHU_RGB
      #undef GRN
      #undef GRN_RGB
      #undef SPG
      #undef SPG_RGB
      #undef CYN
      #undef CYN_RGB
      #undef AZU
      #undef AZU_RGB
      #undef TEA
      #undef TEA_RGB
      #undef TUR
      #undef TUR_RGB
      #undef BLU
      #undef BLU_RGB
      #undef PUR
      #undef PUR_RGB
      #undef MAJ
      #undef MAJ_RGB
      #undef PNK
      #undef PNK_RGB
      #undef WHT
      #undef WHT_RGB
      #undef BLK
      #undef BLK_RGB
      #undef ___
      #undef DUG
      #undef DUG_RGB
      #undef LAC
      #undef LAC_RGB

      #undef BSL
      #undef BNL
      #undef BCL

      #undef SSL
      #undef SNL
      #undef SCL

      #undef FST
      #undef WRP
      #undef SLO
    #endif

};
